# CEC1702 register map
Vendor: Microchip Technology; Series: CEC1702Q; File version: 0
CPU: CM4 r1p0, little endian, MPU, FPU, 3 interrupt priority bits, 155 interrupts
Registers are 32-bit, read-write, reset 0x0 unless marked. A register's access mark holds for its fields unless they carry their own. Offsets are from the block's base; [hi:lo] are bit positions; {n}, {i} and the like mark numbered series.

## GPIO — GPIO Pin Control Registers
Base 0x40081000; register names take the prefix GPIO_
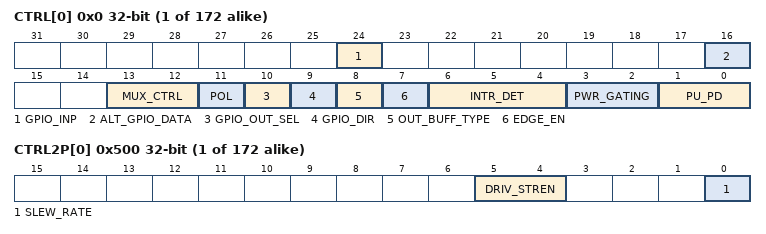
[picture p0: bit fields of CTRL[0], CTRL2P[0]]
{0x0+4i} CTRL[{i}] (i=0..171) — GPIO Pin Control Register
  [24] GPIO_INP — Reads of this bit always return the state of GPIO input from the pad, independent of the Mux selection for the pin or the Direction. This bit is forced high when the selected power well is off as selected by the POWER_GATING field in this register.
  [16] ALT_GPIO_DATA — Reads of this bit always return the last data written to the GPIO output data register bit; reads do not return the current output value of the GPIO pin if it is configured as an output. If the GPIO_OUTPUT_SEL T bit in this register is '1', then this bit is Read Only and the GPIO output data register bit is only written by the GPIO Output Register. If the GPIO_OUTPUT_SELECT bit in this register is '0', then this bit is R/W, and the bit corresponding to this GPIO in the GPIO Output Register is Read Only.
  [13:12] MUX_CTRL — This field determines the active signal function for a pin. 00 = GPIO Function Selected, 01 = Signal Function 1 Selected, 10 = Signal Function 2 Selected, 11 = Signal Function 3 Selected.
  [11] POL — When the Polarity bit is set to '1' and the MUX_CONTROL bits are greater than '00', the selected signal function outputs are inverted and Interrupt Detection sense is inverted. When the MUX_CONTROL field selects the GPIO signal function (Mux='00'), the. Polarity bit does not effect the output. Regardless of the state of the MUX_CONTROL field and the Polarity bit, the state of the pin is always reported without inversion in the GPIO input register. 1=Inverted; 0=Non-inverted
  [10] GPIO_OUT_SEL — This control bit determines which register is used to update the data register for GPIO outputs. 0=GPIO output data for this GPIO come from the ALTERNATE_GPIO_DATA field of this register; writes to the bit representing this GPIO in the GPIO Output Register do not affect the GPIO; 1=GPIO output data for this GPIO come from the bit representing this GPIO in the GPIO Output Register; writes to the ALTERNATE_GPIO_DATA field of this register do not affect the GPIO.
  [9] GPIO_DIR — This bit controls the buffer direction only when the MUX_CONTROL field is '00' selecting the pin signal function to be GPIO. When the MUX_CONTROL field is greater than '00' (i.e., a non-GPIO signal function is selected) this bit has no affect and the selected signal function logic directly controls the pin direction. 0 = Input, 1 = Output
  [8] OUT_BUFF_TYPE — Unless explicitly stated otherwise, pins with (I/O/OD) or (O/OD) in their buffer type column in the tables are compliant with the following Programmable OD/PP Multiplexing Design Rule: Each compliant pin has a programmable open drain/push-pull buffer controlled by the Output Buffer Type bit in the associated Pin Control Register. The state of this bit controls the mode of the interface buffer for all selected functions, including the GPIO function. 0 = Push-Pull, 1 = Open Drain
  [7] EDGE_EN — When combined with the field INTERRUPT_DETECTION in this register, determines the interrupt capability of the GPIO input. 0 = Edge detection disabled, 1 = Edge detection enabled
  [6:4] INTR_DET — When combined with the field INTERRUPT_DETECTION in this register, determines the interrupt capability of the GPIO input. 0 000 = Low Level Sensitive. 0 001 = High Level Sensitive. 0 100 = Interrupt events are disabled. 1 101 = Rising Edge Triggered. 1 110 = Falling Edge Triggered. 1 111 = Either edge triggered
  [3:2] PWR_GATING — The GPIO pin will be tristated when the selected power well is off. 00 = VTR Power Rail, 01 = VCC Main Power Rail (as determined by the VCC_PWRGD input), 1x = Reserved
  [1:0] PU_PD — These bits are used to enable an internal pull-up or pull-down resistor. 00 = None, 01 = Pull Up Enabled, 10 = Pull Down Enabled, 11 = None
{0x300+4i} PARIN[{i}] (i=0..5) — The GPIO Input Registers.
{0x380+4i} PAROUT[{i}] (i=0..5) — The GPIO Output Registers.
{0x500+4i} CTRL2P[{i}] (i=0..171) — The GPIO PIN_CTRL2 Registers
  [5:4] DRIV_STREN — These bits are used to select the drive strength on the pin. The drive strength is the same whether the pin is powered by 3.3V or 1.8V. 00 = 2mA, 01 = 4mA, 10 = 8mA, 11 = 12mA
  [0] SLEW_RATE — This bit is used to select the slew rate on the pin. 0 = slow (half frequency), 1 = fast

## Notices in the file
Copyright (c) 2023 Microchip Technology Inc.
SPDX-License-Identifier: Apache-2.0
Licensed under the Apache License, Version 2.0 (the "License");
you may not use this file except in compliance with the License.
You may obtain a copy of the License at
http://www.apache.org/licenses/LICENSE-2.0
Unless required by applicable law or agreed to in writing, software
distributed under the License is distributed on an "AS IS" BASIS,
WITHOUT WARRANTIES OR CONDITIONS OF ANY KIND, either express or implied.
See the License for the specific language governing permissions and
limitations under the License.
